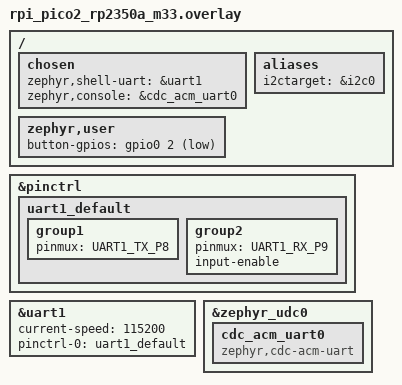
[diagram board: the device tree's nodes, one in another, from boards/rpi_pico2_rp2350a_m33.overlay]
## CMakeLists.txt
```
# SPDX-License-Identifier: Apache-2.0

cmake_minimum_required(VERSION 3.20.0)

find_package(Zephyr REQUIRED HINTS $ENV{ZEPHYR_BASE})
project(test_rpi)

target_sources(app PRIVATE src/main.c src/processing.c)
target_sources_ifdef(CONFIG_BOARD_NATIVE_SIM app PRIVATE src/emul.c)
```

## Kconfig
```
config TEST_RPI_LOG_LEVEL
	int "Default log level for test_rpi"
	default 4

source "Kconfig.zephyr"
```

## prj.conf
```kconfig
CONFIG_LOG=y
# Default log level:
# 0: Logging OFF
# 1: ERROR
# 2: WARNING
# 3: INFO
# 4: DEBUG
CONFIG_LOG_DEFAULT_LEVEL=1
CONFIG_TEST_RPI_LOG_LEVEL=4
CONFIG_LOG_FUNC_NAME_PREFIX_ERR=y
CONFIG_LOG_FUNC_NAME_PREFIX_DBG=y
CONFIG_GPIO=y
CONFIG_CONSOLE=y
CONFIG_SHELL=y
# Don't output log messages in the shell terminal
CONFIG_SHELL_LOG_BACKEND=n
CONFIG_I2C=y
CONFIG_I2C_TARGET=y
```

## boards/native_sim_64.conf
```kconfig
CONFIG_ENTROPY_GENERATOR=y
CONFIG_TEST_RANDOM_GENERATOR=y
CONFIG_EMUL=y
CONFIG_GPIO_EMUL=y
CONFIG_I2C_EMUL=y
```

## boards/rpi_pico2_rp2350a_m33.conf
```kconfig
CONFIG_USB_DEVICE_STACK=y
CONFIG_USB_CDC_ACM=y
CONFIG_USB_CDC_ACM_LOG_LEVEL_OFF=y
CONFIG_USB_DEVICE_INITIALIZE_AT_BOOT=y

# Use the UART console as the log backend
CONFIG_LOG_BACKEND_UART=y

CONFIG_SOC_RP2350A_M33_SECOND_CORE=y
```

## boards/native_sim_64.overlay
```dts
/*
 * Copyright (c) 2025 Igalia S.L.
 * Author: Ricardo Cañuelo Navarro <rcn@igalia.com>
 *
 * SPDX-License-Identifier: Apache-2.0
 */

/ {
	aliases {
		i2ctarget = &i2c0;
	};

	zephyr,user {
		button-gpios = <&gpio0 0 GPIO_ACTIVE_HIGH>;
	};
};
```

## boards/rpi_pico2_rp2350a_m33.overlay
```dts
/*
 * Copyright (c) 2025 Igalia S.L.
 * Author: Ricardo Cañuelo Navarro <rcn@igalia.com>
 *
 * SPDX-License-Identifier: Apache-2.0
 */

/ {
	chosen {
		zephyr,shell-uart = &uart1;
		zephyr,console = &cdc_acm_uart0;
	};

	aliases {
		i2ctarget = &i2c0;
	};

	zephyr,user {
		button-gpios = <&gpio0 2 (GPIO_ACTIVE_LOW | GPIO_PULL_UP)>;
	};
};

&pinctrl {
	uart1_default: uart1_default {
		group1 {
			pinmux = <UART1_TX_P8>;
		};
		group2 {
			pinmux = <UART1_RX_P9>;
			input-enable;
		};
	};
};

&uart1 {
	current-speed = <115200>;
	status = "okay";
	pinctrl-0 = <&uart1_default>;
	pinctrl-names = "default";
};

&zephyr_udc0 {
	cdc_acm_uart0: cdc_acm_uart0 {
		compatible = "zephyr,cdc-acm-uart";
	};
};
```

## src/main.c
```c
/*
 * Copyright (c) 2025 Igalia S.L.
 * Author: Ricardo Cañuelo Navarro <rcn@igalia.com>
 *
 * SPDX-License-Identifier: Apache-2.0
 */

#include <string.h>
#include <zephyr/logging/log.h>
#include <zephyr/kernel.h>
#include <zephyr/sys/printk.h>
#include <zephyr/drivers/gpio.h>
#include <zephyr/drivers/i2c.h>
#include "common.h"

#define THREAD_STACKSIZE	2048
#define THREAD_PRIORITY		10

LOG_MODULE_REGISTER(test_rpi, CONFIG_TEST_RPI_LOG_LEVEL);

K_MSGQ_DEFINE(in_msgq, sizeof(int), 1, 1);
K_MSGQ_DEFINE(out_msgq, PROC_MSG_SIZE, 1, 1);

K_THREAD_STACK_DEFINE(processing_stack, THREAD_STACKSIZE);

static char str_data[PROC_MSG_SIZE];
K_MUTEX_DEFINE(str_data_mutex);

/*
 * Get button configuration from the devicetree zephyr,user node.
 */
#define ZEPHYR_USER_NODE DT_PATH(zephyr_user)
const struct gpio_dt_spec button = GPIO_DT_SPEC_GET_OR(
	ZEPHYR_USER_NODE, button_gpios, {0});

/*
 * Get I2C device configuration from the devicetree i2ctarget alias.
 * Check node availability at buid time.
 */
#define I2C_NODE	DT_ALIAS(i2ctarget)
#if !DT_NODE_HAS_STATUS_OKAY(I2C_NODE)
#error "Unsupported board: i2ctarget devicetree alias is not defined"
#endif
const struct device *i2c_target = DEVICE_DT_GET(I2C_NODE);
/* I2C data structures */
static char i2cbuffer[PROC_MSG_SIZE];
static int i2cidx = -1;
static i2c_register_t i2creg = I2C_REG_DEFAULT;

/*
 * Callback called on a write request from the controller.
 */
int write_requested_cb(struct i2c_target_config *config)
{
	LOG_DBG("I2C WRITE start");
	return 0;
}

/*
 * Callback called when a byte was received on an ongoing write request
 * from the controller.
 */
int write_received_cb(struct i2c_target_config *config, uint8_t val)
{
	LOG_DBG("I2C WRITE: 0x%02x", val);
	i2creg = val;
	if (val == I2C_REG_UPTIME)
		i2cidx = -1;

	return 0;
}

/*
 * Callback called on a read request from the controller.
 * If it's a first read, load the output buffer contents from the
 * current contents of the source data buffer (str_data).
 *
 * The data byte sent to the controller is pointed to by val.
 * Returns:
 *   0 if there's additional data to send
 *   -ENOMEM if the byte sent is the end of the data transfer
 *   -EIO if the selected register isn't supported
 */
int read_requested_cb(struct i2c_target_config *config, uint8_t *val)
{
	if (i2creg != I2C_REG_UPTIME)
		return -EIO;

	LOG_DBG("I2C READ started. i2cidx: %d", i2cidx);
	if (i2cidx < 0) {
		/* Copy source buffer to the i2c output buffer */
		k_mutex_lock(&str_data_mutex, K_FOREVER);
		strncpy(i2cbuffer, str_data, PROC_MSG_SIZE);
		k_mutex_unlock(&str_data_mutex);
	}
	i2cidx++;
	if (i2cidx == PROC_MSG_SIZE) {
		i2cidx = -1;
		return -ENOMEM;
	}
	*val = i2cbuffer[i2cidx];
	LOG_DBG("I2C READ send: 0x%02x", *val);

	return 0;
}

/*
 * Callback called on a continued read request from the
 * controller. We're implementing repeated start semantics, so this will
 * always return -ENOMEM to signal that a new START request is needed.
 */
int read_processed_cb(struct i2c_target_config *config, uint8_t *val)
{
	LOG_DBG("I2C READ continued");
	return -ENOMEM;
}

/*
 * Callback called on a stop request from the controller. Rewinds the
 * index of the i2c data buffer to prepare for the next send.
 */
int stop_cb(struct i2c_target_config *config)
{
	i2cidx = -1;
	LOG_DBG("I2C STOP");
	return 0;
}

static struct i2c_target_callbacks target_callbacks = {
	.write_requested = write_requested_cb,
	.write_received = write_received_cb,
	.read_requested = read_requested_cb,
	.read_processed = read_processed_cb,
	.stop = stop_cb,
};


/*
 * Deferred irq work triggered by the GPIO IRQ callback
 * (button_pressed). This should run some time after the ISR, at which
 * point the button press should be stable after the initial bouncing.
 *
 * Checks the button status and sends the current system uptime in
 * seconds through in_msgq if the the button is still pressed.
 */
static void debounce_expired(struct k_work *work)
{
	ARG_UNUSED(work);

	unsigned int data = k_uptime_seconds();

	if (gpio_pin_get_dt(&button))
		k_msgq_put(&in_msgq, &data, K_NO_WAIT);
}

static K_WORK_DELAYABLE_DEFINE(debounce_work, debounce_expired);

/*
 * Callback function for the button GPIO IRQ.
 * De-bounces the button press by scheduling the processing into a
 * workqueue.
 */
void button_pressed(const struct device *dev, struct gpio_callback *cb,
		    uint32_t pins)
{
	ARG_UNUSED(dev);
	ARG_UNUSED(cb);
	ARG_UNUSED(pins);

	k_work_reschedule(&debounce_work, K_MSEC(30));
}

struct k_thread processing_thread;

int main(void)
{
	static struct gpio_callback button_cb_data;
	int ret;

	struct i2c_target_config target_cfg = {
		.address = I2C_ADDR,
		.callbacks = &target_callbacks,
	};

	if (i2c_target_register(i2c_target, &target_cfg) < 0) {
		LOG_ERR("Failed to register target");
		return -1;
	}

	/* Button/GPIO setup */
	if (!gpio_is_ready_dt(&button)) {
		LOG_ERR("Error: button device %s is not ready",
		       button.port->name);
		return 0;
	}
	ret = gpio_pin_configure_dt(&button, GPIO_INPUT);
	if (ret != 0) {
		LOG_ERR("Error %d: failed to configure %s pin %d",
		       ret, button.port->name, button.pin);
		return 0;
	}
	ret = gpio_pin_interrupt_configure_dt(&button,
					      GPIO_INT_EDGE_TO_ACTIVE);
	if (ret != 0) {
		LOG_ERR("Error %d: failed to configure interrupt on %s pin %d",
			ret, button.port->name, button.pin);
		return 0;
	}
	gpio_init_callback(&button_cb_data, button_pressed, BIT(button.pin));
	gpio_add_callback(button.port, &button_cb_data);

	/* Thread initialization */
	k_thread_create(&processing_thread, processing_stack,
			THREAD_STACKSIZE, data_process,
			&in_msgq, &out_msgq, NULL,
			THREAD_PRIORITY, 0, K_FOREVER);
	k_thread_name_set(&processing_thread, "processing");
	k_thread_start(&processing_thread);

	/* DBG: Main loop */
	while (1) {
		char buffer[PROC_MSG_SIZE];

		k_msgq_get(&out_msgq, buffer, K_FOREVER);
		LOG_DBG("Received: %s", buffer);
		k_mutex_lock(&str_data_mutex, K_FOREVER);
		strncpy(str_data, buffer, PROC_MSG_SIZE);
		k_mutex_unlock(&str_data_mutex);
	}
	return 0;
}
```

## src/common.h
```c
/*
 * Copyright (c) 2025 Igalia S.L.
 * Author: Ricardo Cañuelo Navarro <rcn@igalia.com>
 *
 * SPDX-License-Identifier: Apache-2.0
 */

#ifndef _COMMON_H
#define _COMMON_H

#include <zephyr/drivers/gpio.h>

#define PROC_MSG_SIZE		8
#define THREAD_STACKSIZE	2048
#define THREAD_PRIORITY		10
#define I2C_ADDR		0x60

typedef enum {
	I2C_REG_UPTIME,
	I2C_REG_NOT_SUPPORTED,

	I2C_REG_DEFAULT = I2C_REG_UPTIME
} i2c_register_t;

void data_process(void *p1, void *p2, void *p3);

#endif
```

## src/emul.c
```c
/*
 * Copyright (c) 2025 Igalia S.L.
 * Author: Ricardo Cañuelo Navarro <rcn@igalia.com>
 *
 * SPDX-License-Identifier: Apache-2.0
 */

#include <zephyr/kernel.h>
#include <zephyr/shell/shell.h>
#include <zephyr/sys/printk.h>
#include <zephyr/drivers/gpio.h>
#include <zephyr/drivers/i2c.h>
#include <zephyr/random/random.h>
#include <zephyr/drivers/gpio/gpio_emul.h>
#include <zephyr/drivers/i2c_emul.h>
#include "common.h"

LOG_MODULE_DECLARE(test_rpi, CONFIG_TEST_RPI_LOG_LEVEL);

extern const struct gpio_dt_spec button;
extern const struct device *i2c_target;

/*
 * A real controller may want to continue reading after the first
 * received byte. We're implementing repeated-start semantics so we'll
 * only be sending one byte per transfer, but we need to allocate space
 * for an extra byte to process the possible additional read request.
 */
static uint8_t emul_read_buf[2];

/*
 * Emulates a single I2C READ START request from a controller.
 */
static uint8_t *i2c_emul_read(void)
{
	struct i2c_msg msg;
	int ret;

	msg.buf = emul_read_buf;
	msg.len = sizeof(emul_read_buf);
	msg.flags = I2C_MSG_RESTART | I2C_MSG_READ;
	ret = i2c_transfer(i2c_target, &msg, 1, I2C_ADDR);
	if (ret == -EIO)
		return NULL;

	return emul_read_buf;
}

static void i2c_emul_write(uint8_t *data, int len)
{
	struct i2c_msg msg;

	/*
	 * NOTE: It's not explicitly said anywhere that msg.buf can be
	 * NULL even if msg.len is 0. The behavior may be
	 * driver-specific and prone to change so we're being safe here
	 * by using a 1-byte buffer.
	 */
	msg.buf = data;
	msg.len = len;
	msg.flags = I2C_MSG_WRITE;
	i2c_transfer(i2c_target, &msg, 1, I2C_ADDR);
}

/*
 * Emulates an explicit I2C STOP sent from a controller.
 */
static void i2c_emul_stop(void)
{
	struct i2c_msg msg;
	uint8_t buf = 0;

	/*
	 * NOTE: It's not explicitly said anywhere that msg.buf can be
	 * NULL even if msg.len is 0. The behavior may be
	 * driver-specific and prone to change so we're being safe here
	 * by using a 1-byte buffer.
	 */
	msg.buf = &buf;
	msg.len = 0;
	msg.flags = I2C_MSG_WRITE | I2C_MSG_STOP;
	i2c_transfer(i2c_target, &msg, 1, I2C_ADDR);
}

/*
 * Emulates an I2C "UPTIME" command request from a controller using
 * repeated start.
 */
static void i2c_emul_uptime(const struct shell *sh, size_t argc, char **argv)
{
	uint8_t buffer[PROC_MSG_SIZE] = {0};
	i2c_register_t reg = I2C_REG_UPTIME;
	int i;

	i2c_emul_write((uint8_t *)&reg, 1);
	for (i = 0; i < PROC_MSG_SIZE; i++) {
		uint8_t *b = i2c_emul_read();
		if (b == NULL)
			break;
		buffer[i] = *b;
	}
	i2c_emul_stop();

	if (i == PROC_MSG_SIZE) {
		shell_print(sh, "%s", buffer);
	} else {
		shell_print(sh, "Transfer error");
	}
}

/*
 * Emulates a button press with bouncing.
 */
static void button_press(void)
{
	const struct device *dev = device_get_binding(button.port->name);
	int n_bounces = sys_rand8_get() % 10;
	int state = 1;
	int i;

	/* Press */
	gpio_emul_input_set(dev, 0, state);
	/* Bouncing */
	for (i = 0; i < n_bounces; i++) {
		state = state ? 0: 1;
		k_busy_wait(1000 * (sys_rand8_get() % 10));
		gpio_emul_input_set(dev, 0, state);
	}
	/* Stabilization */
	gpio_emul_input_set(dev, 0, 1);
	k_busy_wait(100000);
	/* Release */
	gpio_emul_input_set(dev, 0, 0);
}

SHELL_CMD_REGISTER(buttonpress, NULL, "Simulates a button press", button_press);
SHELL_CMD_REGISTER(i2cread, NULL, "Simulates an I2C read request", i2c_emul_read);
SHELL_CMD_REGISTER(i2cuptime, NULL, "Simulates an I2C uptime request", i2c_emul_uptime);
SHELL_CMD_REGISTER(i2cstop, NULL, "Simulates an I2C stop request", i2c_emul_stop);
```

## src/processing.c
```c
/*
 * Copyright (c) 2025 Igalia S.L.
 * Author: Ricardo Cañuelo Navarro <rcn@igalia.com>
 *
 * SPDX-License-Identifier: Apache-2.0
 */

#include <stdio.h>
#include <zephyr/logging/log.h>
#include <zephyr/kernel.h>
#include <zephyr/sys/printk.h>
#include "common.h"

LOG_MODULE_DECLARE(test_rpi, CONFIG_TEST_RPI_LOG_LEVEL);

static char data_out[PROC_MSG_SIZE];

/*
 * Receives a message on the message queue passed in p1, does some
 * processing on the data received and sends a response on the message
 * queue passed in p2.
 */
void data_process(void *p1, void *p2, void *p3)
{
	struct k_msgq *inq = p1;
	struct k_msgq *outq = p2;
	ARG_UNUSED(p3);

	while (1) {
		unsigned int data;

		k_msgq_get(inq, &data, K_FOREVER);
		LOG_DBG("Received: %d", data);

		/* Data processing: convert integer to string */
		snprintf(data_out, sizeof(data_out), "%d", data);

		k_msgq_put(outq, data_out, K_NO_WAIT);
	}
}
```
